# STM32L552 register map
File version: 1.1
Registers are 32-bit, read-write, reset 0x0 unless marked. A register's access mark holds for its fields unless they carry their own. Offsets are from the block's base; [hi:lo] are bit positions; lines under a group give offsets from that group; {n}, {i} and the like mark numbered series; 'fields as' and 'values as' point back to an identical list.

## COMP — Comparator
Base 0x40010200
Same registers: SEC_COMP 0x50010200
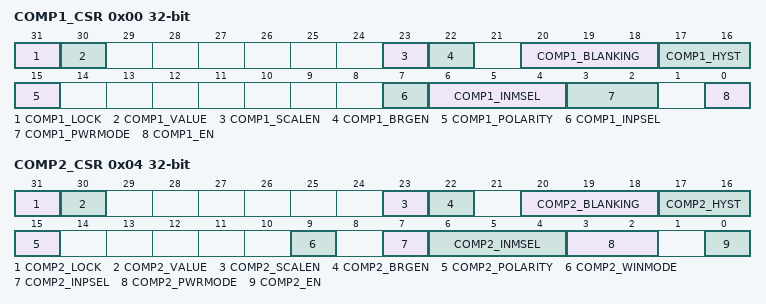
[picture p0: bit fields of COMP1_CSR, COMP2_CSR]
0x00 COMP1_CSR access per field — Comparator 1 control and status register
  [31] COMP1_LOCK wo — COMP1_CSR register lock bit
  [30] COMP1_VALUE ro — Comparator 1 output status bit
  [23] COMP1_SCALEN rw — Voltage scaler enable bit
  [22] COMP1_BRGEN rw — Scaler bridge enable
  [20:18] COMP1_BLANKING rw — Comparator 1 blanking source selection bits
  [17:16] COMP1_HYST rw — Comparator 1 hysteresis selection bits
  [15] COMP1_POLARITY rw — Comparator 1 polarity selection bit
  [7] COMP1_INPSEL rw — Comparator1 input plus selection bit
  [6:4] COMP1_INMSEL rw — Comparator 1 Input Minus connection configuration bit
  [3:2] COMP1_PWRMODE rw — Power Mode of the comparator 1
  [0] COMP1_EN rw — Comparator 1 enable bit
0x04 COMP2_CSR access per field — Comparator 2 control and status register
  [31] COMP2_LOCK wo — COMP2_CSR register lock bit
  [30] COMP2_VALUE ro — Comparator 2 output status bit
  [23] COMP2_SCALEN rw — Voltage scaler enable bit
  [22] COMP2_BRGEN rw — Scaler bridge enable
  [20:18] COMP2_BLANKING rw — Comparator 2 blanking source selection bits
  [17:16] COMP2_HYST rw — Comparator 2 hysteresis selection bits
  [15] COMP2_POLARITY rw — Comparator 2 polarity selection bit
  [9] COMP2_WINMODE rw — Windows mode selection bit
  [7] COMP2_INPSEL rw — Comparator 2 Input Plus connection configuration bit
  [6:4] COMP2_INMSEL rw — Comparator 2 Input Minus connection configuration bit
  [3:2] COMP2_PWRMODE rw — Power Mode of the comparator 2
  [0] COMP2_EN rw — Comparator 2 enable bit

## VREFBUF — Voltage reference buffer
Base 0x40010030
Same registers: SEC_VREFBUF 0x50010030
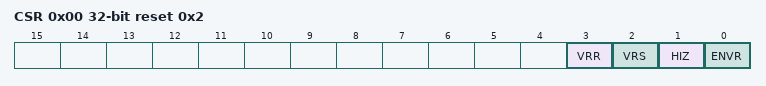
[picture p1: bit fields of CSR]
0x00 CSR access per field reset 0x2 — VREF control and status register
  [3] VRR ro — Voltage reference buffer ready
  [2] VRS rw — Voltage reference scale
  [1] HIZ rw — High impedance mode
  [0] ENVR rw — Voltage reference buffer enable
0x04 CCR — calibration control register
  [5:0] TRIM — Trimming code

## TSC — Touch sensing controller
Base 0x40024000
Same registers: SEC_TSC 0x50024000
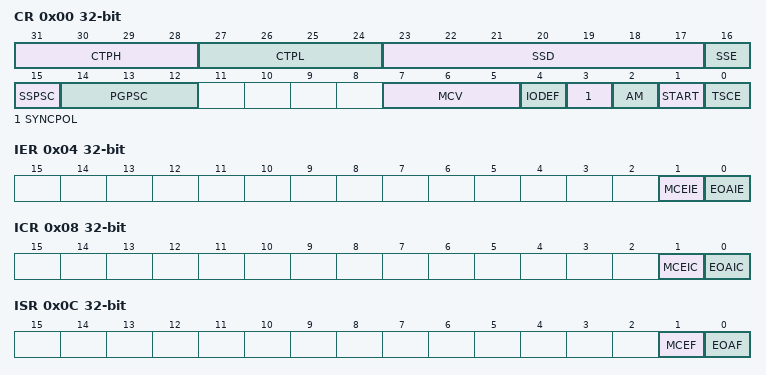
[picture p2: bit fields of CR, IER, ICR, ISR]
0x00 CR — control register
  [31:28] CTPH — Charge transfer pulse high
  [27:24] CTPL — Charge transfer pulse low
  [23:17] SSD — Spread spectrum deviation
  [16] SSE — Spread spectrum enable
  [15] SSPSC — Spread spectrum prescaler
  [14:12] PGPSC — pulse generator prescaler
  [7:5] MCV — Max count value
  [4] IODEF — I/O Default mode
  [3] SYNCPOL — Synchronization pin polarity
  [2] AM — Acquisition mode
  [1] START — Start a new acquisition
  [0] TSCE — Touch sensing controller enable
0x04 IER — interrupt enable register
  [1] MCEIE — Max count error interrupt enable
  [0] EOAIE — End of acquisition interrupt enable
0x08 ICR — interrupt clear register
  [1] MCEIC — Max count error interrupt clear
  [0] EOAIC — End of acquisition interrupt clear
0x0C ISR — interrupt status register
  [1] MCEF — Max count error flag
  [0] EOAF — End of acquisition flag
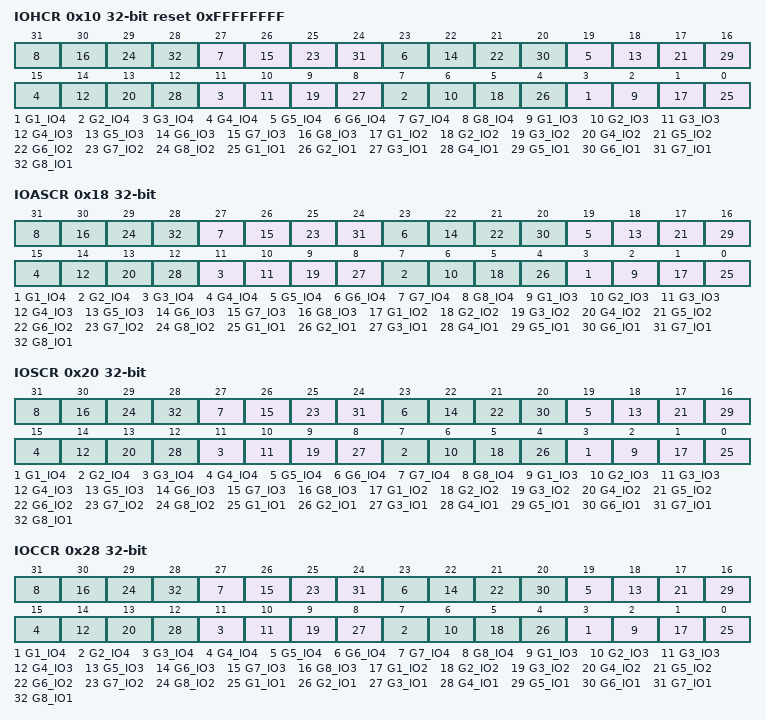
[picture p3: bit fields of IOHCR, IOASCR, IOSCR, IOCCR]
0x10 IOHCR reset 0xFFFFFFFF — I/O hysteresis control register
  [4n-1] G{n}_IO4 (n=1..8), [4n-2] G{n}_IO3 (n=1..8), [4n-3] G{n}_IO2 (n=1..8), [4n-4] G{n}_IO1 (n=1..8)
0x18 IOASCR — I/O analog switch control register
  fields as IOHCR
0x20 IOSCR — I/O sampling control register
  fields as IOHCR
0x28 IOCCR — I/O channel control register
  fields as IOHCR
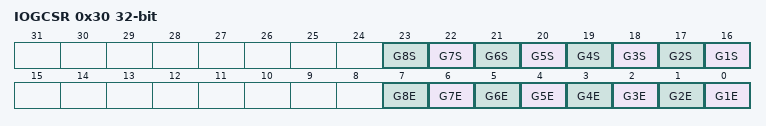
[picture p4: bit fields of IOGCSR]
0x30 IOGCSR access per field — I/O group control status register
  [n+15] G{n}S ro (n=1..8) — Analog I/O group x status
  [n-1] G{n}E rw (n=1..8) — Analog I/O group x enable
{0x30+4i} IOG{i}CR ro (i=1..8) — I/O group x counter register
  [13:0] CNT — Counter value

## UCPD1 — USB Power Delivery interface
Base 0x4000DC00
Same registers: SEC_UCPD1 0x5000DC00
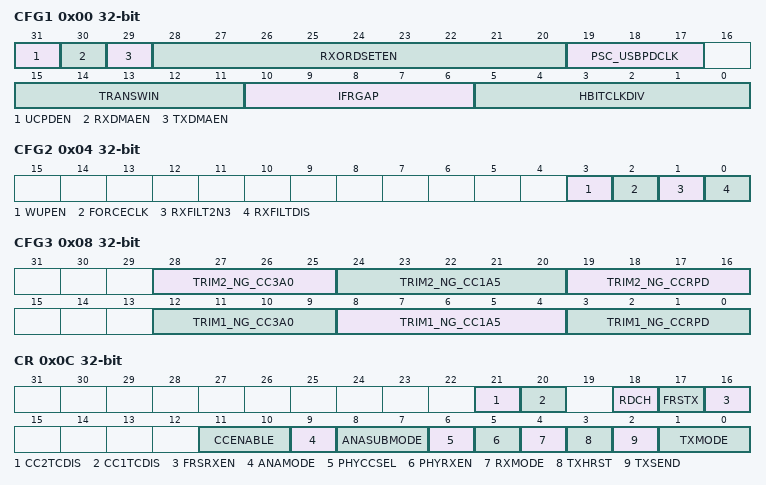
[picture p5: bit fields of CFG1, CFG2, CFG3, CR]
0x00 CFG1 — UCPD configuration register
  [31] UCPDEN, [30] RXDMAEN, [29] TXDMAEN, [28:20] RXORDSETEN, [19:17] PSC_USBPDCLK, [15:11] TRANSWIN, [10:6] IFRGAP, [5:0] HBITCLKDIV
0x04 CFG2 — UCPD configuration register 2
  [3] WUPEN, [2] FORCECLK, [1] RXFILT2N3, [0] RXFILTDIS
0x08 CFG3 — UCPD configuration register 3
  [28:25] TRIM2_NG_CC3A0, [24:20] TRIM2_NG_CC1A5, [19:16] TRIM2_NG_CCRPD, [12:9] TRIM1_NG_CC3A0, [8:4] TRIM1_NG_CC1A5, [3:0] TRIM1_NG_CCRPD
0x0C CR — UCPD control register
  [21] CC2TCDIS, [20] CC1TCDIS, [18] RDCH, [17] FRSTX, [16] FRSRXEN, [11:10] CCENABLE, [9] ANAMODE, [8:7] ANASUBMODE, [6] PHYCCSEL, [5] PHYRXEN, [4] RXMODE, [3] TXHRST, [2] TXSEND, [1:0] TXMODE
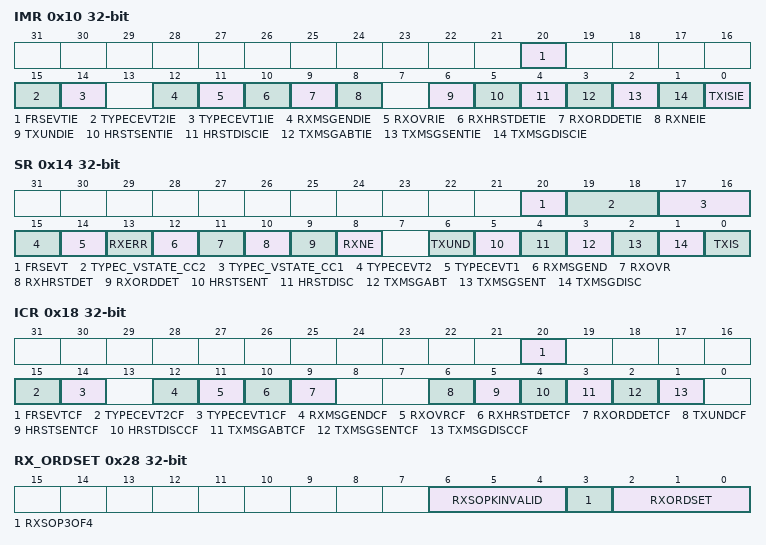
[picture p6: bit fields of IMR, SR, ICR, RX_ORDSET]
0x10 IMR — UCPD Interrupt Mask Register
  [20] FRSEVTIE, [15] TYPECEVT2IE, [14] TYPECEVT1IE, [12] RXMSGENDIE, [11] RXOVRIE, [10] RXHRSTDETIE, [9] RXORDDETIE, [8] RXNEIE, [6] TXUNDIE, [5] HRSTSENTIE, [4] HRSTDISCIE, [3] TXMSGABTIE, [2] TXMSGSENTIE, [1] TXMSGDISCIE, [0] TXISIE
0x14 SR ro — UCPD Status Register
  [20] FRSEVT, [19:18] TYPEC_VSTATE_CC2, [17:16] TYPEC_VSTATE_CC1, [15] TYPECEVT2, [14] TYPECEVT1, [13] RXERR, [12] RXMSGEND, [11] RXOVR, [10] RXHRSTDET, [9] RXORDDET, [8] RXNE, [6] TXUND, [5] HRSTSENT, [4] HRSTDISC, [3] TXMSGABT, [2] TXMSGSENT, [1] TXMSGDISC, [0] TXIS
0x18 ICR — UCPD Interrupt Clear Register
  [20] FRSEVTCF, [15] TYPECEVT2CF, [14] TYPECEVT1CF, [12] RXMSGENDCF, [11] RXOVRCF, [10] RXHRSTDETCF, [9] RXORDDETCF, [6] TXUNDCF, [5] HRSTSENTCF, [4] HRSTDISCCF, [3] TXMSGABTCF, [2] TXMSGSENTCF, [1] TXMSGDISCCF
0x1C TX_ORDSET — UCPD Tx Ordered Set Type Register
  [19:0] TXORDSET
0x20 TX_PAYSZ — UCPD Tx Paysize Register
  [9:0] TXPAYSZ
0x24 TXDR — UCPD Tx Data Register
  [7:0] TXDATA
0x28 RX_ORDSET ro — UCPD Rx Ordered Set Register
  [6:4] RXSOPKINVALID, [3] RXSOP3OF4, [2:0] RXORDSET
0x2C RX_PAYSZ ro — UCPD Rx Paysize Register
  [9:0] RXPAYSZ
0x30 RXDR ro — UCPD Receive Data Register
  [7:0] RXDATA
0x34 RX_ORDEXT1 — UCPD Rx Ordered Set Extension Register
  [19:0] RXSOPX1
0x38 RX_ORDEXT2 — UCPD Rx Ordered Set Extension Register
  [19:0] RXSOPX2
